# 3066H register map
File version: 1.0
Registers are 32-bit, access per field, reset 0x0 unless marked. A register's access mark holds for its fields unless they carry their own. Offsets are from the block's base; [hi:lo] are bit positions.

## SPI0 — SPI0 peripheral interface
Base 0x14200000
Same registers: SPI1 0x14201000, SPI2 0x14202000
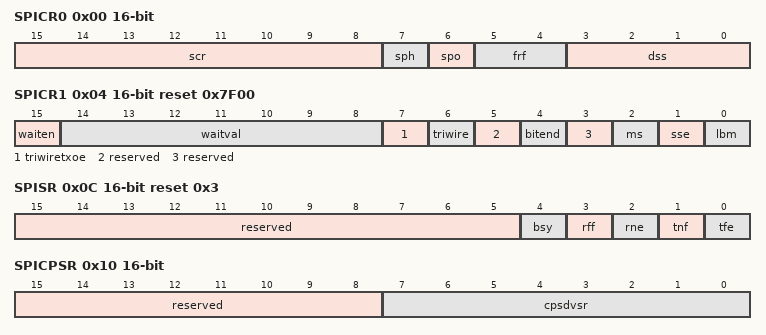
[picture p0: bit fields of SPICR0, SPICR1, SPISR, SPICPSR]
0x00 SPICR0 16-bit rw — SPICR0为控制寄存器0。
  [15:8] scr — 串行时钟率，取值范围0～255。scr的值用来产生SPI发送和接收的速率，公式为Fclk_spi/( cpsdvsr x (1+scr))? cpsdvsr是一个2～254之间的偶数，由寄存器SPICPSR配置。
  [7] sph — SPICLKOUT相位，具体含义请参见“25.4 接口时序”的SPI帧格式。
  [6] spo — SPICLKOUT极性，具体含义请参见“25.4 接口时序”的SPI帧格式。
  [5:4] frf — 帧格式选择。 00：Motorola SPI帧格式； 01：TI同步串行帧格式； 10：National Microwire帧格式； 11：保留。
  [3:0] dss — 设置数据位宽。 0x3：4bit； 0x4：5bit； 0x5：6bit； 0x6：7bit； 0x7：8bit； 0x8：9bit； 0x9：10bit； 0xA：11bit； 0xB：12bit； 0xC：13bit； 0xD：14bit； 0xE：15bit； 0xF：16bit； 其他：保留。
0x04 SPICR1 16-bit reset 0x7F00 — SPICR1为控制寄存器1。
  [15] waiten rw — 等待使能，当SPICR1寄存器的sm配置为Master模式且SPICR0寄存器的frf配置为Microwire帧格式时有效。 0：不使能； 1：使能。
  [14:8] waitval rw — Microwire帧格式时，写和读之间的等待拍数。当SPICR1寄存器的sm配置为Master模式且waiten为1并且帧格式为National Microwire时有效。 0x00：等待周期为1个工作时钟clk_spi； 0x01：等待周期为2个工作时钟clk_spi； … 0x7F：等待周期为128个工作时钟clk_spi。
  [7] triwiretxoe rw — 三线模式数据线方向控制位。 0：双向数据线方向为接收； 1：双向数据线方向为发送。 只能在frf位域配置为Motorola SPI帧格式时使用。
  [6] triwire rw — 三线/四线模式配置位。 0：四线模式； 1：三线模式。 只能在frf位域配置为Motorola SPI帧格式时使用。
  [5] reserved ro — 保留。
  [4] bitend rw — 数据正反序控制位。 0：数据顺序为MSB到LSB； 1：数据顺序为LSB到MSB。
  [3] reserved ro — 保留。
  [2] ms rw — 设置Master或者Slave模式，此位只能在SPI不使能时改变。 0：Master模式； 1：Slave模式。
  [1] sse rw — 设置SPI使能。 0：不使能； 1：使能。
  [0] lbm rw — 设置环回模式。 0：正常的串行接口操作使能； 1：发送串行移位寄存器的输出在内部连接到接收串行移位寄存器的输入上。
0x08 SPIDR 16-bit rw — SPIDR为数据寄存器。
  [15:0] data — 发送/接收FIFO。 读：从接收FIFO读出数据； 写：向发送FIFO写入数据。 如果数据bit数少于16则必须右对齐。SPI控制器发送时将忽略高位未使用的bit位，SPI控制器接收时则自动将数据右对齐。
0x0C SPISR 16-bit ro reset 0x3 — SPISR为状态寄存器。
  [15:5] reserved — 保留。
  [4] bsy — SPI忙标记。 0：空闲； 1：忙。
  [3] rff — 接收FIFO是否已满。 0：未满； 1：已满。
  [2] rne — 接收FIFO是否未空。 0：已空； 1：未空。
  [1] tnf — 发送FIFO是否未满。 0：已满； 1：未满。
  [0] tfe — 发送FIFO是否已空。 0：未空； 1：已空。
0x10 SPICPSR 16-bit — SPICPSR为时钟分频寄存器。
  [15:8] reserved ro — 保留。
  [7:0] cpsdvsr rw — 时钟分频因子。此值必须是2～254之间的偶数，取决于输入时钟SPI_CLK的频率。最低位读作“0”。
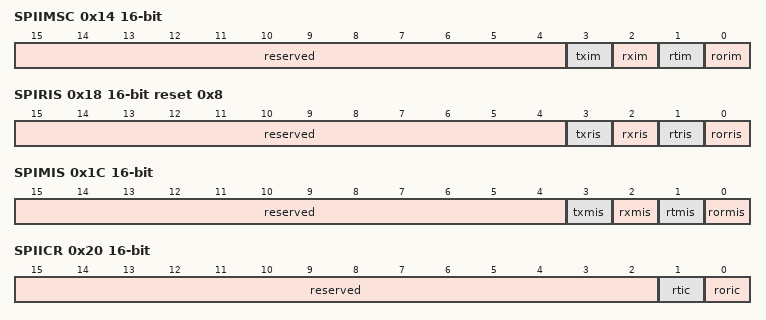
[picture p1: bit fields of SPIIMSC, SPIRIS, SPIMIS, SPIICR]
0x14 SPIIMSC 16-bit — SPIIMSC为中断屏蔽寄存器。
  [15:4] reserved ro — 保留。
  [3] txim rw — 发送FIFO中断屏蔽。 0：发送FIFO中断被屏蔽，不使能； 1：发送FIFO中断未被屏蔽，使能。
  [2] rxim rw — 接收FIFO中断屏蔽。 0：接收FIFO中断被屏蔽，不使能； 1：接收FIFO中断未被屏蔽，使能。
  [1] rtim rw — 接收超时中断。 0：接收超时中断屏蔽，不使能； 1：接收超时中断不屏蔽，使能。
  [0] rorim rw — 接收溢出中断屏蔽。 0：接收FIFO溢出中断屏蔽，不使能； 1：接收FIFO溢出中断不屏蔽，使能。
0x18 SPIRIS 16-bit ro reset 0x8 — SPIRIS为原始中断状态寄存器。值“0”表示无中断，值“1”表示有中断。
  [15:4] reserved — 保留。
  [3] txris — 发送FIFO中断的原始中断状态。 0：大于SPITXFIFOCR[txintsize]中配置的中断水线； 1：等于或小于SPITXFIFOCR[txintsize]中配置的中断水线。
  [2] rxris — 接收FIFO中断的原始中断状态。 0：小于SPIRXFIFOCR[rxintsize]中配置的中断水线； 1：等于或大于SPIRXFIFOCR[rxintsize]中配置的中断水线。
  [1] rtris — 接收超时中断的原始中断状态。当接收FIFO非空且SPI_CLK未发生翻转，超过64个SPI工作时钟周期时，此位域置1。对SPIICR[rtic]写1，可清除此位域。
  [0] rorris — 接收溢出中断的原始中断状态。当接收FIFO已满且额外的数据被接收时，发生溢出中断，此位域置1。对SPIICR[roric]写1，可清除此位域。
0x1C SPIMIS 16-bit ro — SPIMIS为屏蔽后中断状态寄存器。值“0”表示无中断，值“1”表示有中断。
  [15:4] reserved — 保留。
  [3] txmis — 发送FIFO中断屏蔽后的状态。
  [2] rxmis — 接收FIFO中断屏蔽后的状态。
  [1] rtmis — 接收超时中断屏蔽后的状态。
  [0] rormis — 接收溢出中断屏蔽后的状态。
0x20 SPIICR 16-bit — SPIICR为中断清除寄存器。写“1”清除中断，写“0”无影响。
  [15:2] reserved ro — 保留。
  [1] rtic rw write-clears — 清除接收超时中断。
  [0] roric rw write-clears — 清除接收溢出中断。
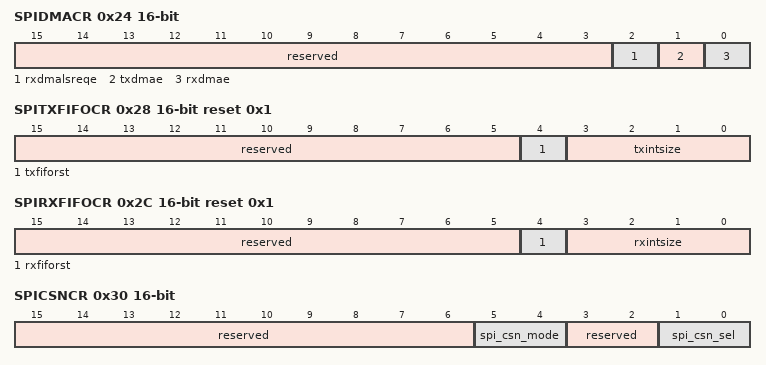
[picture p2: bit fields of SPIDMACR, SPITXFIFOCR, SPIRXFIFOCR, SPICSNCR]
0x24 SPIDMACR 16-bit — SPIDMACR为DMA控制寄存器。
  [15:3] reserved ro — 保留位。
  [2] rxdmalsreqe rw — 接收 FIFO DMA外设流控（SPI流控）使能寄存器。当RX FIFO非空且SPI超时，LSREQ硬件请求线置1。 0：禁止； 1：使能。
  [1] txdmae rw — 发送FIFO DMA请求使能寄存器。 0：禁止； 1：使能。
  [0] rxdmae rw — 接收FIFO DMA请求使能寄存器。 0：禁止； 1：使能。
0x28 SPITXFIFOCR 16-bit reset 0x1 — SPITXFIFOCR为发送FIFO控制寄存器。
  [15:5] reserved ro — 保留。
  [4] txfiforst rw — 发送FIFO软复位配置位。 0：发送FIFO软复位； 1：发送FIFO解除软复位。
  [3:0] txintsize rw — 配置发送FIFO的水线。当发送FIFO中的数据个数满足条件时，产生发送 FIFO中断（TXRIS）。如果使能了发送FIFO DMA功能，同时产生发送FIFO DMA burst传输请求。 0x0：等于0； 0x1：小于或等于1； 0x2：小于或等于2； 0x3：小于或等于3； … 0xF：小于或等于15。 如果DMA控制器配置为搬移FIFO的数据，那么发送FIFO的水线需要小于DMA控制器的Burst长度。
0x2C SPIRXFIFOCR 16-bit reset 0x1 — SPIRXFIFOCR为接收FIFO控制寄存器。
  [15:5] reserved ro — 保留。
  [4] rxfiforst rw — 接收FIFO软复位配置位。 0：接收FIFO软复位； 1：接收FIFO解除软复位。
  [3:0] rxintsize rw — 配置接收FIFO的水线。当接收FIFO中的数据个数满足条件时，产生接收FIFO中断（RXRIS）。如果使能了接收FIFO DMA功能，产生接收FIFO DMA burst传输请求。 0x0：大于或等于0； 0x1：大于或等于1； 0x2：大于或等于2； 0x3：大于或等于3； … 0xF：大于或等于15。 如果DMA控制器配置为搬移FIFO的数据，那么接收FIFO的水线需要大于DMA控制器的Burst长度。
0x30 SPICSNCR 16-bit — SPICSNCR为SPI片选选择寄存器。
  [15:6] reserved ro — 保留。
  [5:4] spi_csn_mode rw — 配置SPI片选产生的方式。 00：自动。片选信号由MCU逻辑根据所选时序自动产生； 01：altasens模式。当采用Motorola SPI帧格式时，片选信号由SPI使能信号控制，使能后，片选拉低，否则片选拉高； 10：受软件控制，置0； 11：受软件控制，置1。
  [3:2] reserved ro — 保留。
  [1:0] spi_csn_sel rw — 配置选择SPI片选。 00：片选0； 01：片选1； 其他：保留。
